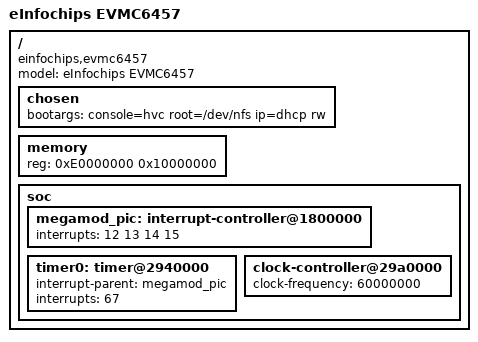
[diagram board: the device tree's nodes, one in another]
// SPDX-License-Identifier: GPL-2.0-or-later
/*
 * arch/c6x/boot/dts/evmc6457.dts
 *
 * EVMC6457 Evaluation Platform For TMS320C6457
 *
 * Copyright (C) 2011 Texas Instruments Incorporated
 *
 * Author: Mark Salter <msalter@redhat.com>
 */

/dts-v1/;

/include/ "tms320c6457.dtsi"

/ {
	model = "eInfochips EVMC6457";
	compatible = "einfochips,evmc6457";

	chosen {
		bootargs = "console=hvc root=/dev/nfs ip=dhcp rw";
	};

	memory {
		device_type = "memory";
		reg = <0xE0000000 0x10000000>;
	};

	soc {
		megamod_pic: interrupt-controller@1800000 {
		       interrupts = < 12 13 14 15 >;
		};

		timer0: timer@2940000 {
			interrupt-parent = <&megamod_pic>;
			interrupts = < 67 >;
		};

		clock-controller@29a0000 {
			clock-frequency = <60000000>;
		};
	};
};
